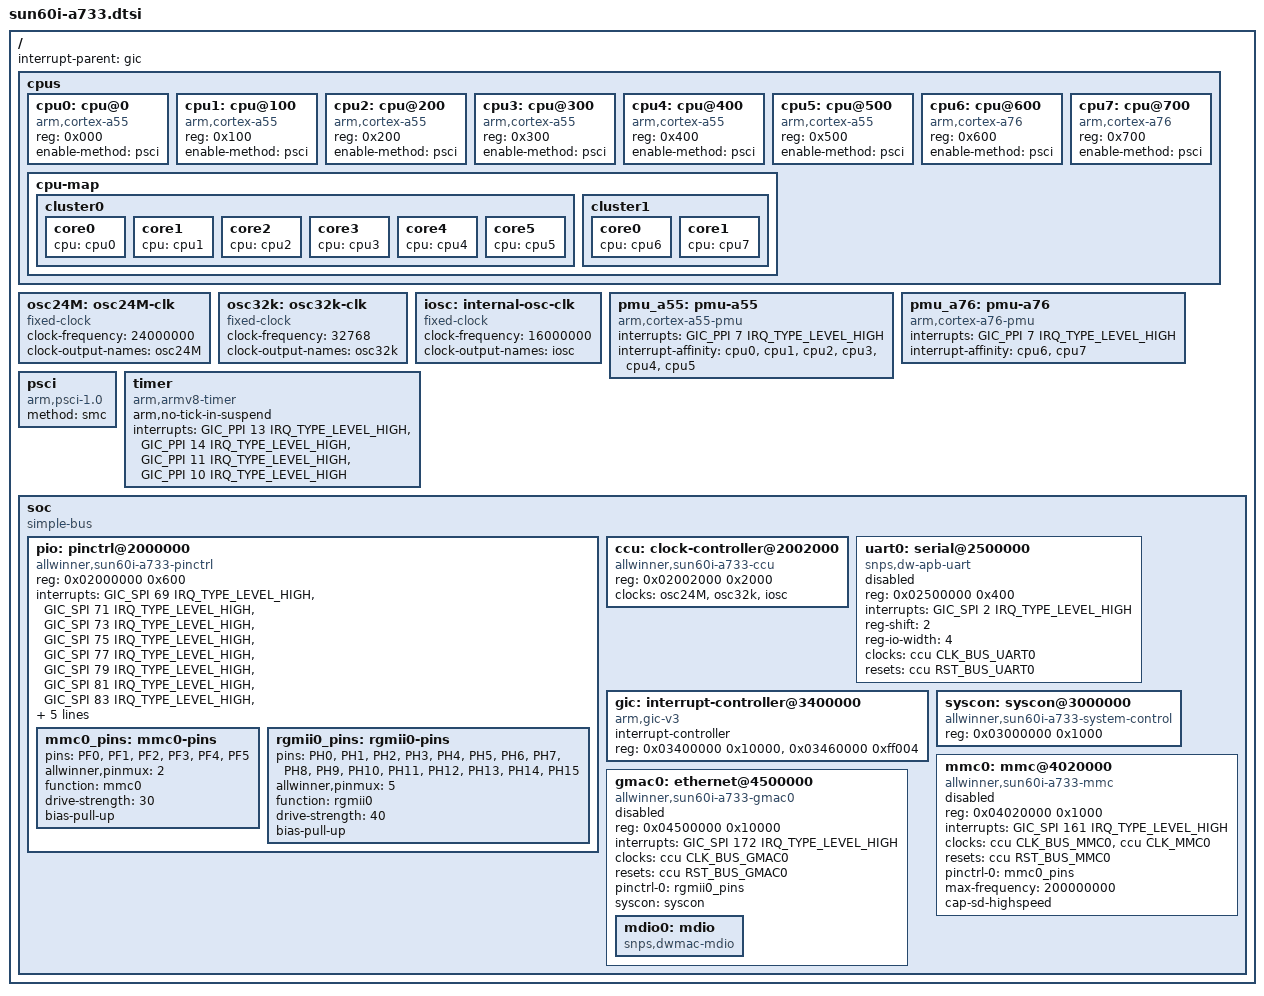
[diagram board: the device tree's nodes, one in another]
// SPDX-License-Identifier: (GPL-2.0-only OR MIT)

#include <dt-bindings/interrupt-controller/arm-gic.h>
#include <dt-bindings/clock/sun60i-a733-ccu.h>
#include <dt-bindings/reset/sun60i-a733-ccu.h>

/ {
	interrupt-parent = <&gic>;
	#address-cells = <2>;
	#size-cells = <2>;

	cpus {
		#address-cells = <1>;
		#size-cells = <0>;

		cpu0: cpu@0 {
			compatible = "arm,cortex-a55";
			device_type = "cpu";
			reg = <0x000>;
			enable-method = "psci";
		};

		cpu1: cpu@100 {
			compatible = "arm,cortex-a55";
			device_type = "cpu";
			reg = <0x100>;
			enable-method = "psci";
		};

		cpu2: cpu@200 {
			compatible = "arm,cortex-a55";
			device_type = "cpu";
			reg = <0x200>;
			enable-method = "psci";
		};

		cpu3: cpu@300 {
			compatible = "arm,cortex-a55";
			device_type = "cpu";
			reg = <0x300>;
			enable-method = "psci";
		};

		cpu4: cpu@400 {
			compatible = "arm,cortex-a55";
			device_type = "cpu";
			reg = <0x400>;
			enable-method = "psci";
		};

		cpu5: cpu@500 {
			compatible = "arm,cortex-a55";
			device_type = "cpu";
			reg = <0x500>;
			enable-method = "psci";
		};

		cpu6: cpu@600 {
			compatible = "arm,cortex-a76";
			device_type = "cpu";
			reg = <0x600>;
			enable-method = "psci";
		};

		cpu7: cpu@700 {
			compatible = "arm,cortex-a76";
			device_type = "cpu";
			reg = <0x700>;
			enable-method = "psci";
		};

		cpu-map {
			cluster0 {
				core0 {
					cpu = <&cpu0>;
				};

				core1 {
					cpu = <&cpu1>;
				};

				core2 {
					cpu = <&cpu2>;
				};

				core3 {
					cpu = <&cpu3>;
				};

				core4 {
					cpu = <&cpu4>;
				};

				core5 {
					cpu = <&cpu5>;
				};
			};

			cluster1 {
				core0 {
					cpu = <&cpu6>;
				};

				core1 {
					cpu = <&cpu7>;
				};
			};
		};
	};

	osc24M: osc24M-clk {
		#clock-cells = <0>;
		compatible = "fixed-clock";
		clock-frequency = <24000000>;
		clock-output-names = "osc24M";
	};

	osc32k: osc32k-clk {
		#clock-cells = <0>;
		compatible = "fixed-clock";
		clock-frequency = <32768>;
		clock-output-names = "osc32k";
	};

	iosc: internal-osc-clk {
		#clock-cells = <0>;
		compatible = "fixed-clock";
		clock-frequency = <16000000>;
		clock-output-names = "iosc";
	};

	pmu_a55: pmu-a55 {
		compatible = "arm,cortex-a55-pmu";
		interrupts = <GIC_PPI 7 IRQ_TYPE_LEVEL_HIGH>;
		interrupt-affinity = <&cpu0>, <&cpu1>, <&cpu2>,
				     <&cpu3>, <&cpu4>, <&cpu5>;
	};

	pmu_a76: pmu-a76 {
		compatible = "arm,cortex-a76-pmu";
		interrupts = <GIC_PPI 7 IRQ_TYPE_LEVEL_HIGH>;
		interrupt-affinity = <&cpu6>, <&cpu7>;
	};

	psci {
		compatible = "arm,psci-1.0", "arm,psci-0.2";
		method = "smc";
	};

	timer {
		compatible = "arm,armv8-timer";
		arm,no-tick-in-suspend;
		interrupts = <GIC_PPI 13 IRQ_TYPE_LEVEL_HIGH>,
			     <GIC_PPI 14 IRQ_TYPE_LEVEL_HIGH>,
			     <GIC_PPI 11 IRQ_TYPE_LEVEL_HIGH>,
			     <GIC_PPI 10 IRQ_TYPE_LEVEL_HIGH>;
	};

	soc {
		compatible = "simple-bus";
		#address-cells = <1>;
		#size-cells = <1>;
		ranges = <0x0 0x0 0x0 0x40000000>;

		pio: pinctrl@2000000 {
			compatible = "allwinner,sun60i-a733-pinctrl";
			reg = <0x02000000 0x600>;
			interrupts = <GIC_SPI 69 IRQ_TYPE_LEVEL_HIGH>,
				     <GIC_SPI 71 IRQ_TYPE_LEVEL_HIGH>,
				     <GIC_SPI 73 IRQ_TYPE_LEVEL_HIGH>,
				     <GIC_SPI 75 IRQ_TYPE_LEVEL_HIGH>,
				     <GIC_SPI 77 IRQ_TYPE_LEVEL_HIGH>,
				     <GIC_SPI 79 IRQ_TYPE_LEVEL_HIGH>,
				     <GIC_SPI 81 IRQ_TYPE_LEVEL_HIGH>,
				     <GIC_SPI 83 IRQ_TYPE_LEVEL_HIGH>,
				     <GIC_SPI 85 IRQ_TYPE_LEVEL_HIGH>,
				     <GIC_SPI 87 IRQ_TYPE_LEVEL_HIGH>;
			clocks = <&ccu CLK_APB1>, <&osc24M>, <&osc32k>;
			clock-names = "apb", "hosc", "losc";
			gpio-controller;
			#gpio-cells = <3>;
			interrupt-controller;
			#interrupt-cells = <3>;

			mmc0_pins: mmc0-pins {
				pins = "PF0", "PF1", "PF2", "PF3", "PF4", "PF5";
				allwinner,pinmux = <2>;
				function = "mmc0";
				drive-strength = <30>;
				bias-pull-up;
			};

			rgmii0_pins: rgmii0-pins {
				pins = "PH0", "PH1", "PH2", "PH3",
				       "PH4", "PH5", "PH6", "PH7",
				       "PH8", "PH9", "PH10", "PH11",
				       "PH12", "PH13", "PH14", "PH15";
				allwinner,pinmux = <5>;
				function = "rgmii0";
				drive-strength = <40>;
				bias-pull-up;
			};
		};

		ccu: clock-controller@2002000 {
			compatible = "allwinner,sun60i-a733-ccu";
			reg = <0x02002000 0x2000>;
			clocks = <&osc24M>, <&osc32k>, <&iosc>;
			clock-names = "hosc", "losc", "iosc";
			#clock-cells = <1>;
			#reset-cells = <1>;
		};

		uart0: serial@2500000 {
			compatible = "snps,dw-apb-uart";
			reg = <0x02500000 0x400>;
			interrupts = <GIC_SPI 2 IRQ_TYPE_LEVEL_HIGH>;
			reg-shift = <2>;
			reg-io-width = <4>;
			clocks = <&ccu CLK_BUS_UART0>;
			resets = <&ccu RST_BUS_UART0>;
			status = "disabled";
		};

		gic: interrupt-controller@3400000 {
			compatible = "arm,gic-v3";
			#address-cells = <1>;
			#interrupt-cells = <3>;
			#size-cells = <1>;
			ranges;
			interrupt-controller;
			reg = <0x03400000 0x10000>,
			      <0x03460000 0xff004>;
		};

		syscon: syscon@3000000 {
			compatible = "allwinner,sun60i-a733-system-control",
				     "allwinner,sun50i-a64-system-control";
			reg = <0x03000000 0x1000>;
			#address-cells = <1>;
			#size-cells = <1>;
			ranges;
		};

		mmc0: mmc@4020000 {
			compatible = "allwinner,sun60i-a733-mmc",
				     "allwinner,sun20i-d1-mmc";
			reg = <0x04020000 0x1000>;
			interrupts = <GIC_SPI 161 IRQ_TYPE_LEVEL_HIGH>;
			clocks = <&ccu CLK_BUS_MMC0>, <&ccu CLK_MMC0>;
			clock-names = "ahb", "mmc";
			resets = <&ccu RST_BUS_MMC0>;
			reset-names = "ahb";
			pinctrl-names = "default";
			pinctrl-0 = <&mmc0_pins>;
			max-frequency = <200000000>;
			cap-sd-highspeed;
			status = "disabled";
			#address-cells = <1>;
			#size-cells = <0>;
		};

		gmac0: ethernet@4500000 {
			compatible = "allwinner,sun60i-a733-gmac0",
				     "allwinner,sun50i-a64-emac";
			reg = <0x04500000 0x10000>;
			interrupts = <GIC_SPI 172 IRQ_TYPE_LEVEL_HIGH>;
			interrupt-names = "macirq";
			clocks = <&ccu CLK_BUS_GMAC0>;
			clock-names = "stmmaceth";
			resets = <&ccu RST_BUS_GMAC0>;
			reset-names = "stmmaceth";
			pinctrl-names = "default";
			pinctrl-0 = <&rgmii0_pins>;
			syscon = <&syscon>;
			status = "disabled";

			mdio0: mdio {
				compatible = "snps,dwmac-mdio";
				#address-cells = <1>;
				#size-cells = <0>;
			};
		};
	};
};
